VERSION ""

NS_ :

BS_:

BU_: BMS Third_Party_Device

BO_ 768 MSGID_0X300: 4 BMS
 SG_ DTC_Flags_2 : 16|16@1+ (1,0) [0|0] ""  Third_Party_Device
 SG_ DTC_Flags_1 : 0|16@1+ (1,0) [0|0] ""  Third_Party_Device

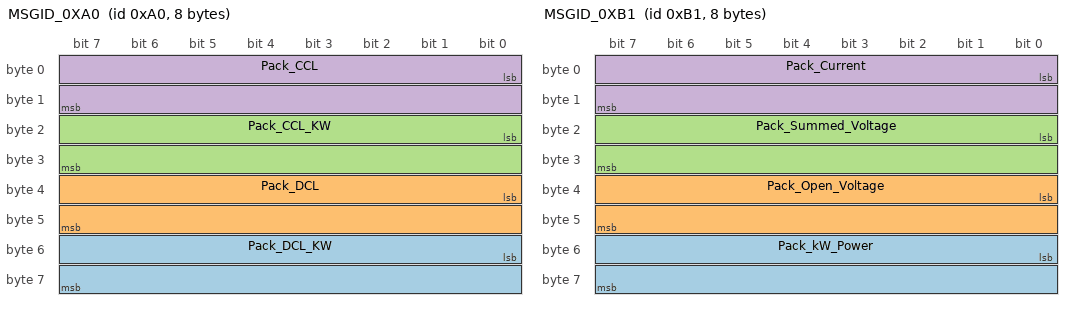
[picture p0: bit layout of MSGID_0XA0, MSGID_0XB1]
BO_ 160 MSGID_0XA0: 8 BMS
 SG_ Pack_DCL_KW : 48|16@1+ (0.1,0) [0|0] "kW"  Third_Party_Device
 SG_ Pack_DCL : 32|16@1+ (1,0) [0|0] "Amps"  Third_Party_Device
 SG_ Pack_CCL_KW : 16|16@1+ (0.1,0) [0|0] "kW"  Third_Party_Device
 SG_ Pack_CCL : 0|16@1+ (1,0) [0|0] "Amps"  Third_Party_Device

BO_ 177 MSGID_0XB1: 8 BMS
 SG_ Pack_kW_Power : 48|16@1+ (0.1,0) [0|0] "kW"  Third_Party_Device
 SG_ Pack_Open_Voltage : 32|16@1+ (0.1,0) [0|0] "Volts"  Third_Party_Device
 SG_ Pack_Summed_Voltage : 16|16@1+ (0.01,0) [0|0] "Volts"  Third_Party_Device
 SG_ Pack_Current : 0|16@1- (0.1,0) [0|0] "Amps"  Third_Party_Device

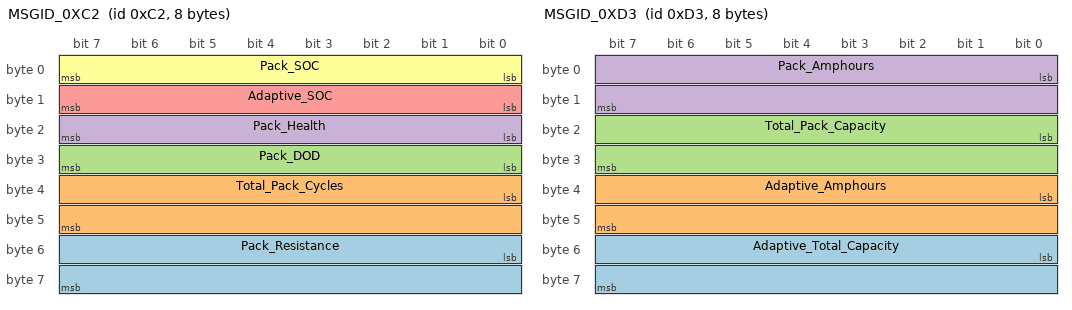
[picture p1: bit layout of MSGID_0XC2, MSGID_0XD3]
BO_ 194 MSGID_0XC2: 8 BMS
 SG_ Pack_Resistance : 48|16@1+ (0.001,0) [0|0] "Ohms"  Third_Party_Device
 SG_ Total_Pack_Cycles : 32|16@1+ (1,0) [0|0] "Num"  Third_Party_Device
 SG_ Pack_DOD : 31|8@0+ (0.5,0) [0|0] "Percent"  Third_Party_Device
 SG_ Pack_Health : 23|8@0+ (1,0) [0|0] "Percent"  Third_Party_Device
 SG_ Adaptive_SOC : 15|8@0+ (0.5,0) [0|0] "Percent"  Third_Party_Device
 SG_ Pack_SOC : 7|8@0+ (0.5,0) [0|0] "Percent"  Third_Party_Device

BO_ 211 MSGID_0XD3: 8 BMS
 SG_ Adaptive_Total_Capacity : 48|16@1+ (0.1,0) [0|0] "Amphours"  Third_Party_Device
 SG_ Adaptive_Amphours : 32|16@1+ (0.1,0) [0|0] "Amphours"  Third_Party_Device
 SG_ Total_Pack_Capacity : 16|16@1+ (0.1,0) [0|0] "Ahr"  Third_Party_Device
 SG_ Pack_Amphours : 0|16@1+ (0.1,0) [0|0] "Amphours"  Third_Party_Device

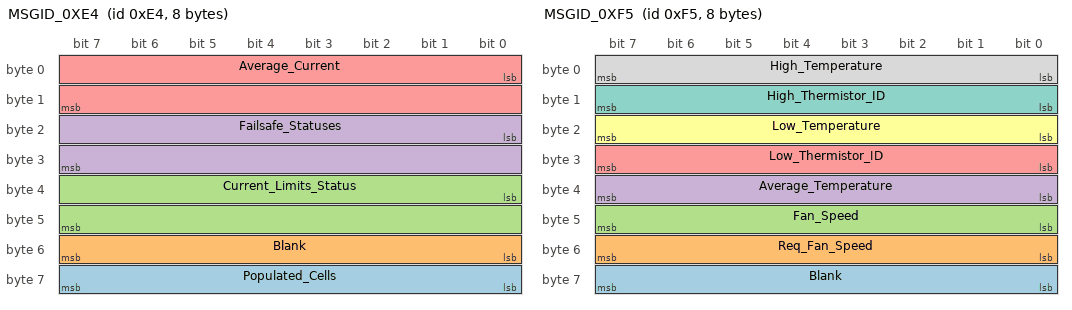
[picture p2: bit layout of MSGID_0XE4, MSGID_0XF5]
BO_ 228 MSGID_0XE4: 8 BMS
 SG_ Populated_Cells : 63|8@0+ (1,0) [0|0] "Num"  Third_Party_Device
 SG_ Blank : 55|8@0+ (1,0) [0|0] ""  Third_Party_Device
 SG_ Current_Limits_Status : 32|16@1+ (1,0) [0|0] ""  Third_Party_Device
 SG_ Failsafe_Statuses : 16|16@1- (1,0) [0|0] ""  Third_Party_Device
 SG_ Average_Current : 0|16@1+ (0.1,0) [0|0] "Amps"  Third_Party_Device

BO_ 245 MSGID_0XF5: 8 BMS
 SG_ Blank : 63|8@0+ (1,0) [0|0] ""  Third_Party_Device
 SG_ Req_Fan_Speed : 55|8@0+ (1,0) [0|0] "Speed"  Third_Party_Device
 SG_ Fan_Speed : 47|8@0+ (1,0) [0|0] "Speed"  Third_Party_Device
 SG_ Average_Temperature : 39|8@0+ (1,0) [0|0] "Celsius"  Third_Party_Device
 SG_ Low_Thermistor_ID : 31|8@0+ (1,0) [0|0] "ID"  Third_Party_Device
 SG_ Low_Temperature : 23|8@0+ (1,0) [0|0] "Celsius"  Third_Party_Device
 SG_ High_Thermistor_ID : 15|8@0+ (1,0) [0|0] "ID"  Third_Party_Device
 SG_ High_Temperature : 7|8@0+ (1,0) [0|0] "Celsius"  Third_Party_Device

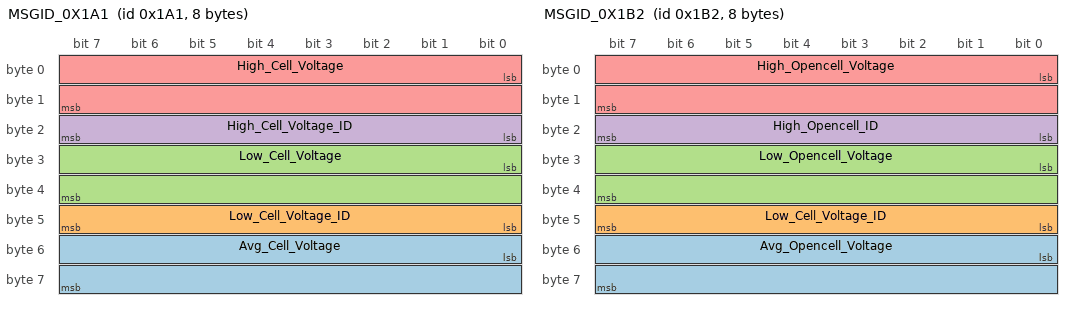
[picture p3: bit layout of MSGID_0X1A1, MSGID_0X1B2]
BO_ 417 MSGID_0X1A1: 8 BMS
 SG_ Avg_Cell_Voltage : 48|16@1+ (0.0001,0) [0|0] "Volts"  Third_Party_Device
 SG_ Low_Cell_Voltage_ID : 47|8@0+ (1,0) [0|0] "ID"  Third_Party_Device
 SG_ Low_Cell_Voltage : 24|16@1+ (0.0001,0) [0|0] "Volts"  Third_Party_Device
 SG_ High_Cell_Voltage_ID : 23|8@0+ (1,0) [0|0] "ID"  Third_Party_Device
 SG_ High_Cell_Voltage : 0|16@1+ (0.0001,0) [0|0] "Volts"  Third_Party_Device

BO_ 434 MSGID_0X1B2: 8 BMS
 SG_ Avg_Opencell_Voltage : 48|16@1+ (0.0001,0) [0|0] "Volts"  Third_Party_Device
 SG_ Low_Cell_Voltage_ID : 47|8@0+ (1,0) [0|0] "ID"  Third_Party_Device
 SG_ Low_Opencell_Voltage : 24|16@1+ (0.0001,0) [0|0] "Volts"  Third_Party_Device
 SG_ High_Opencell_ID : 23|8@0+ (1,0) [0|0] "ID"  Third_Party_Device
 SG_ High_Opencell_Voltage : 0|16@1+ (0.0001,0) [0|0] "Volts"  Third_Party_Device

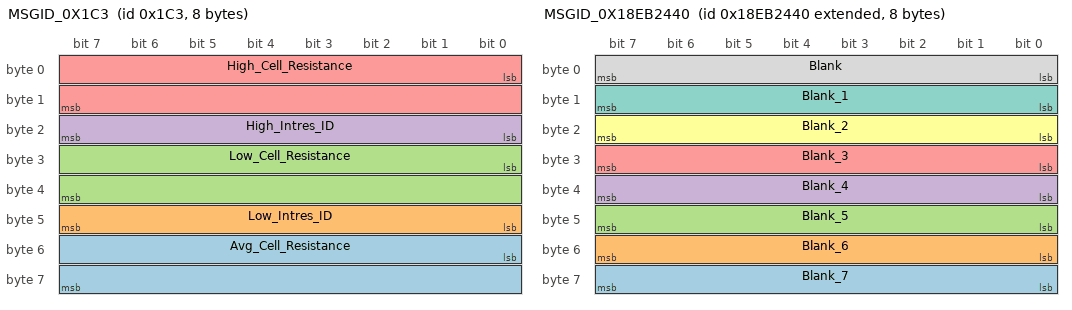
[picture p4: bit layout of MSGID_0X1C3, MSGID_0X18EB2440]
BO_ 451 MSGID_0X1C3: 8 BMS
 SG_ Avg_Cell_Resistance : 48|16@1+ (0.01,0) [0|0] "mOhm"  Third_Party_Device
 SG_ Low_Intres_ID : 47|8@0+ (1,0) [0|0] "ID"  Third_Party_Device
 SG_ Low_Cell_Resistance : 24|16@1+ (0.01,0) [0|0] "mOhm"  Third_Party_Device
 SG_ High_Intres_ID : 23|8@0+ (1,0) [0|0] "ID"  Third_Party_Device
 SG_ High_Cell_Resistance : 0|16@1+ (0.01,0) [0|0] "mOhm"  Third_Party_Device

BO_ 2565547072 MSGID_0X18EB2440: 8 Third_Party_Device
 SG_ Blank_7 : 63|8@0+ (1,0) [0|0] ""  BMS
 SG_ Blank_6 : 55|8@0+ (1,0) [0|0] ""  BMS
 SG_ Blank_5 : 47|8@0+ (1,0) [0|0] ""  BMS
 SG_ Blank_4 : 39|8@0+ (1,0) [0|0] ""  BMS
 SG_ Blank_3 : 31|8@0+ (1,0) [0|0] ""  BMS
 SG_ Blank_2 : 23|8@0+ (1,0) [0|0] ""  BMS
 SG_ Blank_1 : 15|8@0+ (1,0) [0|0] ""  BMS
 SG_ Blank : 7|8@0+ (1,0) [0|0] ""  BMS

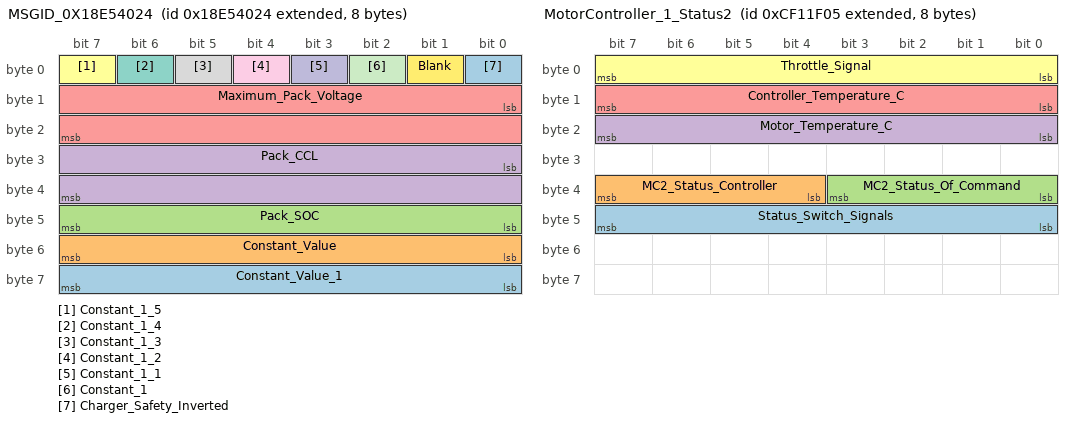
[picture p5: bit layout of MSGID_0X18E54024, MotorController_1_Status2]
BO_ 2565160996 MSGID_0X18E54024: 8 BMS
 SG_ Constant_Value_1 : 63|8@0+ (1,255) [0|0] ""  Third_Party_Device
 SG_ Constant_Value : 55|8@0+ (1,255) [0|0] ""  Third_Party_Device
 SG_ Pack_SOC : 47|8@0+ (17.5,0) [0|5] "Percent"  Third_Party_Device
 SG_ Pack_CCL : 24|16@1- (6553.5,3200) [0|0] "Amps"  Third_Party_Device
 SG_ Maximum_Pack_Voltage : 8|16@1+ (0.1,0) [0|0] "Volts"  Third_Party_Device
 SG_ Constant_1_5 : 7|1@1+ (1,0) [0|1] ""  Third_Party_Device
 SG_ Constant_1_4 : 6|1@1+ (1,0) [0|1] ""  Third_Party_Device
 SG_ Constant_1_3 : 5|1@1+ (1,0) [0|1] ""  Third_Party_Device
 SG_ Constant_1_2 : 4|1@1+ (1,0) [0|1] ""  Third_Party_Device
 SG_ Constant_1_1 : 3|1@1+ (1,0) [0|1] ""  Third_Party_Device
 SG_ Constant_1 : 2|1@1+ (1,0) [0|1] ""  Third_Party_Device
 SG_ Blank : 1|1@1+ (1,0) [0|1] ""  Third_Party_Device
 SG_ Charger_Safety_Inverted : 0|1@1+ (1,0) [0|1] ""  Third_Party_Device

BO_ 2364612101 MotorController_1_Status1: 8 Vector__XXX
 SG_ Fault_MC_ERR15 : 63|1@1+ (1,0) [0|0] "" Vector__XXX
 SG_ Fault_MC_ERR14 : 62|1@1+ (1,0) [0|0] "" Vector__XXX
 SG_ Fault_MC_ERR13 : 61|1@1+ (1,0) [0|0] "" Vector__XXX
 SG_ Fault_MC_ERR12 : 60|1@1+ (1,0) [0|0] "" Vector__XXX
 SG_ Fault_MC_ERR11 : 59|1@1+ (1,0) [0|0] "" Vector__XXX
 SG_ Fault_MC_ERR10 : 58|1@1+ (1,0) [0|0] "" Vector__XXX
 SG_ Fault_MC_ERR9 : 57|1@1+ (1,0) [0|0] "" Vector__XXX
 SG_ Fault_MC_ERR8 : 56|1@1+ (1,0) [0|0] "" Vector__XXX
 SG_ Fault_MC_ERR7 : 55|1@1+ (1,0) [0|0] "" Vector__XXX
 SG_ Fault_MC_ERR6 : 54|1@1+ (1,0) [0|0] "" Vector__XXX
 SG_ Fault_MC_ERR5 : 53|1@1+ (1,0) [0|0] "" Vector__XXX
 SG_ Fault_MC_ERR4 : 52|1@1+ (1,0) [0|0] "" Vector__XXX
 SG_ Fault_MC_ERR3 : 51|1@1+ (1,0) [0|0] "" Vector__XXX
 SG_ Fault_MC_ERR2 : 50|1@1+ (1,0) [0|0] "" Vector__XXX
 SG_ Fault_MC_ERR1 : 49|1@1+ (1,0) [0|0] "" Vector__XXX
 SG_ Fault_MC_ERR0 : 48|1@1+ (1,0) [0|0] "" Vector__XXX
 SG_ Battery_Voltage_V : 32|16@1+ (0.1,0) [0|180] "V" Vector__XXX
 SG_ Actual_Current_A : 16|16@1+ (0.1,0) [0|400] "A" Vector__XXX
 SG_ Actual_Speed_RPM : 0|16@1+ (1.0,0) [0|6000] "rpm" Vector__XXX

BO_ 2364612357 MotorController_1_Status2: 8 Vector__XXX
 SG_ Status_Switch_Signals : 40|8@1+ (1,0) [0|0] "" Vector__XXX
 SG_ MC2_Status_Controller : 36|4@1+ (1,0) [0|0] "" Vector__XXX
 SG_ MC2_Status_Of_Command : 32|4@1+ (1,0) [0|0] "" Vector__XXX
 SG_ Motor_Temperature_C : 16|8@1- (1.0,-30) [-30|225] "�C" Vector__XXX
 SG_ Controller_Temperature_C : 8|8@1- (1.0,-40) [-40|215] "�C" Vector__XXX
 SG_ Throttle_Signal : 0|8@1+ (0.0196,0) [0|5] "V" Vector__XXX

BO_ 2364612102 MotorController_2_Status1: 8 Vector__XXX
 SG_ Fault_MC_ERR15 : 63|1@1+ (1,0) [0|0] "" Vector__XXX
 SG_ Fault_MC_ERR14 : 62|1@1+ (1,0) [0|0] "" Vector__XXX
 SG_ Fault_MC_ERR13 : 61|1@1+ (1,0) [0|0] "" Vector__XXX
 SG_ Fault_MC_ERR12 : 60|1@1+ (1,0) [0|0] "" Vector__XXX
 SG_ Fault_MC_ERR11 : 59|1@1+ (1,0) [0|0] "" Vector__XXX
 SG_ Fault_MC_ERR10 : 58|1@1+ (1,0) [0|0] "" Vector__XXX
 SG_ Fault_MC_ERR9 : 57|1@1+ (1,0) [0|0] "" Vector__XXX
 SG_ Fault_MC_ERR8 : 56|1@1+ (1,0) [0|0] "" Vector__XXX
 SG_ Fault_MC_ERR7 : 55|1@1+ (1,0) [0|0] "" Vector__XXX
 SG_ Fault_MC_ERR6 : 54|1@1+ (1,0) [0|0] "" Vector__XXX
 SG_ Fault_MC_ERR5 : 53|1@1+ (1,0) [0|0] "" Vector__XXX
 SG_ Fault_MC_ERR4 : 52|1@1+ (1,0) [0|0] "" Vector__XXX
 SG_ Fault_MC_ERR3 : 51|1@1+ (1,0) [0|0] "" Vector__XXX
 SG_ Fault_MC_ERR2 : 50|1@1+ (1,0) [0|0] "" Vector__XXX
 SG_ Fault_MC_ERR1 : 49|1@1+ (1,0) [0|0] "" Vector__XXX
 SG_ Fault_MC_ERR0 : 48|1@1+ (1,0) [0|0] "" Vector__XXX
 SG_ Battery_Voltage_V : 32|16@1+ (0.1,0) [0|180] "V" Vector__XXX
 SG_ Actual_Current_A : 16|16@1+ (0.1,0) [0|400] "A" Vector__XXX
 SG_ Actual_Speed_RPM : 0|16@1+ (1.0,0) [0|6000] "rpm" Vector__XXX

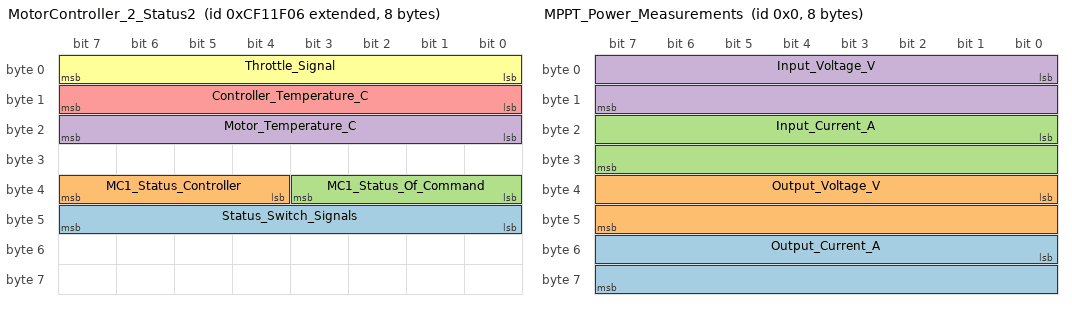
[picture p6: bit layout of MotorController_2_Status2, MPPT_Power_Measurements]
BO_ 2364612358 MotorController_2_Status2: 8 Vector__XXX
 SG_ Status_Switch_Signals : 40|8@1+ (1,0) [0|0] "" Vector__XXX
 SG_ MC1_Status_Controller : 36|4@1+ (1,0) [0|0] "" Vector__XXX
 SG_ MC1_Status_Of_Command : 32|4@1+ (1,0) [0|0] "" Vector__XXX
 SG_ Motor_Temperature_C : 16|8@1- (1.0,-30) [-30|225] "�C" Vector__XXX
 SG_ Controller_Temperature_C : 8|8@1- (1.0,-40) [-40|215] "�C" Vector__XXX
 SG_ Throttle_Signal : 0|8@1+ (0.0196,0) [0|5] "V" Vector__XXX

BO_ 0 MPPT_Power_Measurements: 8 Vector__XXX
 SG_ Output_Current_A : 48|16@1- (0.0005,0) [-16.0|16.0] "A" Vector__XXX
 SG_ Output_Voltage_V : 32|16@1- (0.01,0) [-327.0|327.0] "V" Vector__XXX
 SG_ Input_Current_A : 16|16@1- (0.0005,0) [-16.0|16.0] "A" Vector__XXX
 SG_ Input_Voltage_V : 0|16@1- (0.01,0) [-327.0|327.0] "V" Vector__XXX

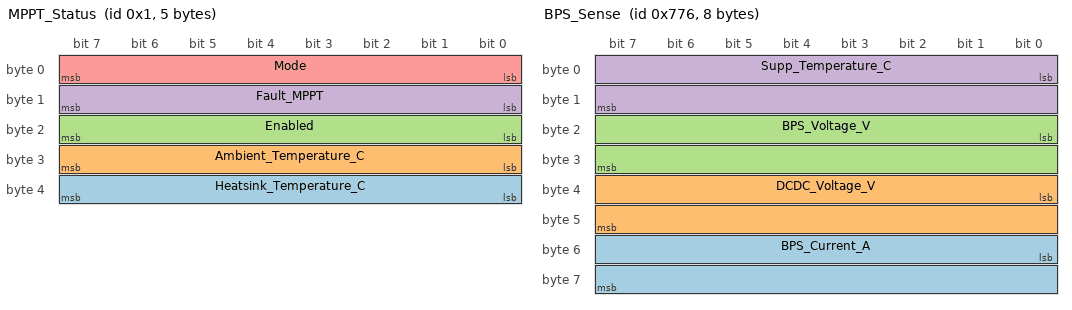
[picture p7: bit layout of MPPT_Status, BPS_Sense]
BO_ 1 MPPT_Status: 5 Vector__XXX
 SG_ Heatsink_Temperature_C : 32|8@1- (1,0) [-128|127] "�C" Vector__XXX
 SG_ Ambient_Temperature_C : 24|8@1- (1,0) [-128|127] "�C" Vector__XXX
 SG_ Enabled : 16|8@1+ (1,0) [0|0] "" Vector__XXX
 SG_ Fault_MPPT : 8|8@1+ (1,0) [0|0] "" Vector__XXX
 SG_ Mode : 0|8@1+ (1,0) [0|0] "" Vector__XXX

BO_ 1910 BPS_Sense: 8 Vector__XXX
 SG_ BPS_Current_A : 48|16@1+ (0.01,0) [0|0] "" Vector__XXX
 SG_ DCDC_Voltage_V : 32|16@1+ (0.01,0) [0|0] "" Vector__XXX
 SG_ BPS_Voltage_V : 16|16@1- (0.01,0) [-318|317] "�C" Vector__XXX
 SG_ Supp_Temperature_C : 0|16@1+ (0.01,0) [0|0] "" Vector__XXX

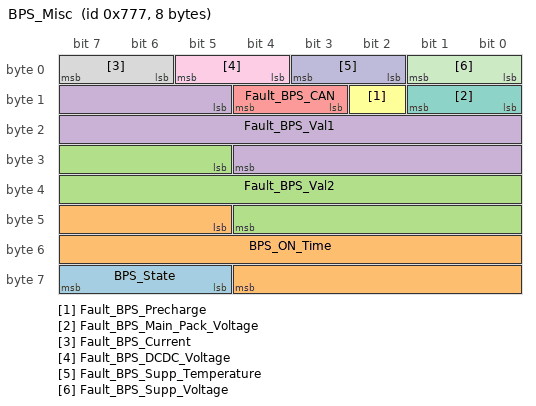
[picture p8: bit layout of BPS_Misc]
BO_ 1911 BPS_Misc: 8 Vector__XXX
 SG_ BPS_State : 61|3@1+ (1,0) [0|0] "" Vector__XXX
 SG_ BPS_ON_Time : 45|16@1+ (0.01,0) [0|0] "" Vector__XXX
 SG_ Fault_BPS_Val2 : 29|16@1+ (0.01,0) [0|0] "" Vector__XXX
 SG_ Fault_BPS_Val1 : 13|16@1+ (0.01,0) [0|0] "" Vector__XXX
 SG_ Fault_BPS_CAN : 11|2@1+ (1,0) [0|0] "" Vector__XXX
 SG_ Fault_BPS_Precharge : 10|1@1+ (1,0) [0|0] "" Vector__XXX
 SG_ Fault_BPS_Main_Pack_Voltage : 8|2@1+ (1,0) [0|0] "" Vector__XXX
 SG_ Fault_BPS_Current : 6|2@1+ (1,0) [0|0] "" Vector__XXX
 SG_ Fault_BPS_DCDC_Voltage : 4|2@1+ (1,0) [0|0] "" Vector__XXX
 SG_ Fault_BPS_Supp_Temperature : 2|2@1+ (1,0) [0|0] "" Vector__XXX
 SG_ Fault_BPS_Supp_Voltage : 0|2@1+ (1,0) [0|0] "" Vector__XXX

CM_ BO_ 768 "This ID Transmits at 8 ms.";
CM_ BO_ 160 "This ID Transmits at 504 ms.";
CM_ BO_ 177 "This ID Transmits at 104 ms.";
CM_ BO_ 194 "This ID Transmits at 1000 ms.";
CM_ BO_ 211 "This ID Transmits at 1000 ms.";
CM_ BO_ 228 "This ID Transmits at 2000 ms.";
CM_ BO_ 245 "This ID Transmits at 2000 ms.";
CM_ BO_ 417 "This ID Transmits at 2000 ms.";
CM_ BO_ 434 "This ID Transmits at 2000 ms.";
CM_ BO_ 451 "This ID Transmits at 2000 ms.";
CM_ BO_ 2565160996 "This ID Transmits at 496 ms.";
BA_DEF_ BO_  "GenMsgCycleTime" INT 0 65535;
BA_DEF_DEF_  "GenMsgCycleTime" 0;
BA_ "GenMsgCycleTime" BO_ 2364612101 50;
BA_ "GenMsgCycleTime" BO_ 2364612357 50;
BA_ "GenMsgCycleTime" BO_ 2364612102 50;
BA_ "GenMsgCycleTime" BO_ 2364612358 50;
BA_ "GenMsgCycleTime" BO_ 0 500;
BA_ "GenMsgCycleTime" BO_ 1 1000;
BA_ "GenMsgCycleTime" BO_ 1910 100;
BA_ "GenMsgCycleTime" BO_ 1911 100;
VAL_ 2364612101 Fault_MC_ERR15 0 "OK" 1 "Hall Galvanometer sensor" ;
VAL_ 2364612101 Fault_MC_ERR14 0 "OK" 1 "Motor over-temperature" ;
VAL_ 2364612101 Fault_MC_ERR13 0 "OK" 1 "Reserved" ;
VAL_ 2364612101 Fault_MC_ERR12 0 "OK" 1 "Reserved" ;
VAL_ 2364612101 Fault_MC_ERR11 0 "OK" 1 "Angle sensor error" ;
VAL_ 2364612101 Fault_MC_ERR10 0 "OK" 1 "Hall throttle is open or short-circuit" ;
VAL_ 2364612101 Fault_MC_ERR9 0 "OK" 1 "Internal reset" ;
VAL_ 2364612101 Fault_MC_ERR8 0 "OK" 1 "Reserved" ;
VAL_ 2364612101 Fault_MC_ERR7 0 "OK" 1 "Throttle error at power-up" ;
VAL_ 2364612101 Fault_MC_ERR6 0 "OK" 1 "Over temperature" ;
VAL_ 2364612101 Fault_MC_ERR5 0 "OK" 1 "Internal volts fault " ;
VAL_ 2364612101 Fault_MC_ERR4 0 "OK" 1 "Stall" ;
VAL_ 2364612101 Fault_MC_ERR3 0 "OK" 1 "Reserved" ;
VAL_ 2364612101 Fault_MC_ERR2 0 "OK" 1 "Low voltage" ;
VAL_ 2364612101 Fault_MC_ERR1 0 "OK" 1 "Over voltage" ;
VAL_ 2364612101 Fault_MC_ERR0 0 "OK" 1 "Identification error" ;
VAL_ 2364612357 MC2_Status_Controller 0 "Stationary" 1 "Forward" 2 "Backward" ;
VAL_ 2364612357 MC2_Status_Of_Command 0 "Neutral" 1 "Forward" 2 "Backward" ;
VAL_ 2364612102 Fault_MC_ERR15 0 "OK" 1 "Hall Galvanometer sensor" ;
VAL_ 2364612102 Fault_MC_ERR14 0 "OK" 1 "Motor over-temperature" ;
VAL_ 2364612102 Fault_MC_ERR13 0 "OK" 1 "Reserved" ;
VAL_ 2364612102 Fault_MC_ERR12 0 "OK" 1 "Reserved" ;
VAL_ 2364612102 Fault_MC_ERR11 0 "OK" 1 "Angle sensor error" ;
VAL_ 2364612102 Fault_MC_ERR10 0 "OK" 1 "Hall throttle is open or short-circuit" ;
VAL_ 2364612102 Fault_MC_ERR9 0 "OK" 1 "Internal reset" ;
VAL_ 2364612102 Fault_MC_ERR8 0 "OK" 1 "Reserved" ;
VAL_ 2364612102 Fault_MC_ERR7 0 "OK" 1 "Throttle error at power-up" ;
VAL_ 2364612102 Fault_MC_ERR6 0 "OK" 1 "Over temperature" ;
VAL_ 2364612102 Fault_MC_ERR5 0 "OK" 1 "Internal volts fault " ;
VAL_ 2364612102 Fault_MC_ERR4 0 "OK" 1 "Stall" ;
VAL_ 2364612102 Fault_MC_ERR3 0 "OK" 1 "Reserved" ;
VAL_ 2364612102 Fault_MC_ERR2 0 "OK" 1 "Low voltage" ;
VAL_ 2364612102 Fault_MC_ERR1 0 "OK" 1 "Over voltage" ;
VAL_ 2364612102 Fault_MC_ERR0 0 "OK" 1 "Identification error" ;
VAL_ 2364612358 MC1_Status_Controller 0 "Stationary" 1 "Forward" 2 "Backward" ;
VAL_ 2364612358 MC1_Status_Of_Command 0 "Neutral" 1 "Forward" 2 "Backward" ;
VAL_ 1 Fault_MPPT 0 "OK" 1 "Configuration Error" 2 "Input Over Voltage" 3 "Output Over Voltage" 4 "Output Over Current" 5 "Input Over Current" 6 "Input Under Current" 7 "Phase Over Current" 8 "General Fault" ;
VAL_ 1911 BPS_State 0 "STANDBY" 1 "PRIMARY" 2 "ACCESSORY" 3 "MPPT_CHARGING" 4 "WALL_CHARGING" 5 "FAULT" ;
VAL_ 1911 Fault_BPS_CAN 0 "OK" 1 "BMS Fault" 2 "Timeout" 3 "Reserved" ;
VAL_ 1911 Fault_BPS_Precharge 0 "OK" 1 "Precharge Fail" 2 "Reserved" 3 "Reserved" ;
VAL_ 1911 Fault_BPS_Main_Pack_Voltage 0 "OK" 1 "Under Voltage" 2 "Over Voltage" 3 "Reserved" ;
VAL_ 1911 Fault_BPS_Current 0 "OK" 1 "Over Current" 2 "Current Sensor Disconnected" 3 "Reserved" ;
VAL_ 1911 Fault_BPS_DCDC_Voltage 0 "OK" 1 "Under Voltage" 2 "Over Voltage" 3 "Reserved" ;
VAL_ 1911 Fault_BPS_Supp_Temperature 0 "OK" 1 "Under Temperature" 2 "Over Temperature" 3 "Reserved" ;
VAL_ 1911 Fault_BPS_Supp_Voltage 0 "OK" 1 "Under Voltage" 2 "Over Voltage" 3 "Reserved" ;
